# ETK-DEMO register map
Vendor: Embedded Toolkit (synthetic demo); File version: 1.0
Embedded Toolkit 演示芯片（合成数据，非真实芯片）
CPU: CM4 r0p1, little endian
Registers are 32-bit, read-write, reset 0x0 unless marked. A register's access mark holds for its fields unless they carry their own. Offsets are from the block's base; lines under a group give offsets from that group; [hi:lo] are bit positions; {n}, {i} and the like mark numbered series; 'fields as' and 'values as' point back to an identical list; <NAME> marks a mode.

## Memory map
0x40010400 EXTI size 0x400 — 外部中断（演示：4 条线）
0x40012C00 TIM1 size 0x400 — 高级定时器（演示）
0x40013800 USART1 size 0x400 — 通用同步/异步收发器（演示）
0x40020000 DMA1 size 0x400 — 直接内存访问控制器（演示：2 个通道，簇结构）
0x40021000 RCC size 0x400 — 复位与时钟控制（演示）
0x48000000 GPIOA size 0x400 — 通用 GPIO（演示：4 个引脚）
0x48000400 GPIOB size 0x400

## Interrupts
6 EXTI0 (EXTI) — EXTI 线 0 中断
11 DMA1_Channel1 (DMA1) — DMA1 通道 1 中断
12 DMA1_Channel2 (DMA1) — DMA1 通道 2 中断
25 TIM1 — TIM1 全局中断
37 USART1 — USART1 全局中断

## GPIOA — 通用 GPIO（演示：4 个引脚）
Base 0x48000000
Same registers: GPIOB 0x48000400
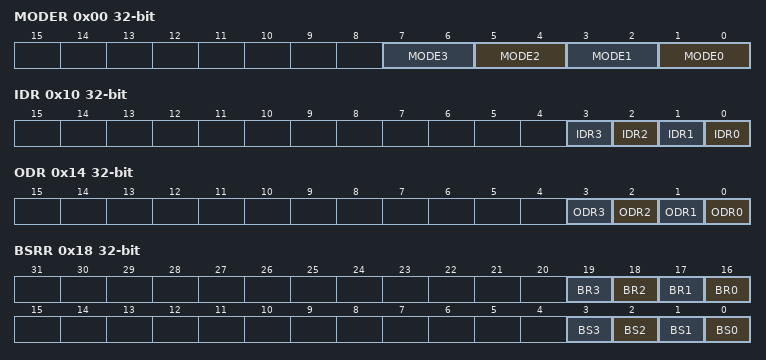
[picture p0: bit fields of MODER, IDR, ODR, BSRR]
0x00 MODER — 模式寄存器（每引脚 2 位）
  [all] fields
    0=INPUT (输入); 1=OUTPUT (输出); 2=ALTERNATE (复用功能); 3=ANALOG (模拟)
  [2n+1:2n] MODE{n} (n=0..3) — 引脚 {n} 模式
0x10 IDR ro — 输入数据寄存器（只读）
  [n] IDR{n} (n=0..3) — 引脚 {n} 输入
0x14 ODR — 输出数据寄存器
  [n] ODR{n} (n=0..3) — 引脚 {n} 输出
0x18 BSRR wo — 位置位/复位寄存器（只写）
  [n+16] BR{n} (n=0..3) — 复位引脚 {n}
  [n] BS{n} (n=0..3) — 置位引脚 {n}

## USART1 — 通用同步/异步收发器（演示）
Base 0x40013800
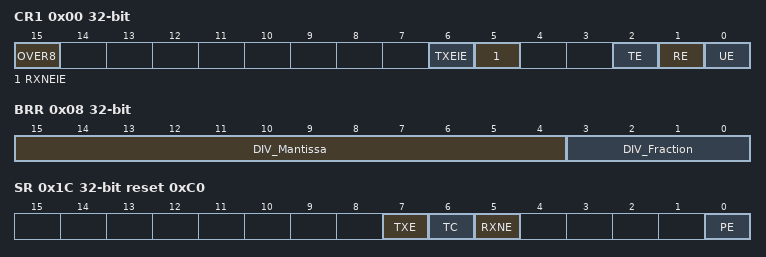
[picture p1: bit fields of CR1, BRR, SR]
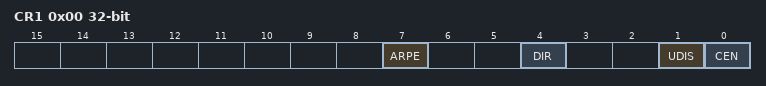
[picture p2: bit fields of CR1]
0x00 CR1 — 控制寄存器 1
  [15] OVER8 — 8 倍过采样
  [6] TXEIE — 发送空中断使能
  [5] RXNEIE — 接收完成中断使能
  [2] TE — 发送使能
  [1] RE — 接收使能
  [0] UE — USART 使能
0x04 DR — 数据寄存器
  [8:0] DR — 收发数据（低 9 位）
0x08 BRR — 波特率寄存器
  [15:4] DIV_Mantissa — 波特率分频整数部分
  [3:0] DIV_Fraction — 波特率分频小数部分
0x1C SR ro reset 0xC0 — 状态寄存器（只读）
  [7] TXE — 发送数据寄存器空
  [6] TC — 发送完成
  [5] RXNE — 接收数据非空
  [0] PE — 校验错误

## TIM1 — 高级定时器（演示）
Base 0x40012C00
0x00 CR1 — 控制寄存器 1
  [7] ARPE — 自动重载预装载使能
  [4] DIR — 计数方向
    0=UP (向上计数); 1=DOWN (向下计数)
  [1] UDIS — 更新事件禁止
  [0] CEN — 计数器使能
0x24 CNT ro — 计数器（只读）
  [15:0] CNT — 当前计数值
0x28 PSC — 预分频器
  [15:0] PSC — 预分频值
0x2C ARR — 自动重载寄存器
  [15:0] ARR — 自动重载值

## RCC — 复位与时钟控制（演示）
Base 0x40021000
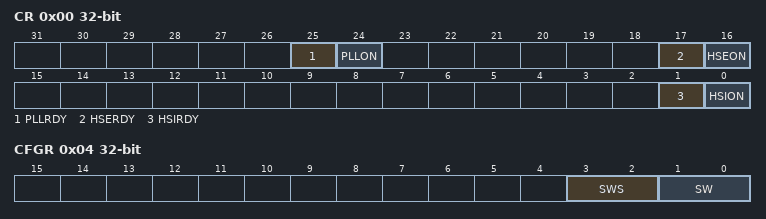
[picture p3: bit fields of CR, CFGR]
0x00 CR — 时钟控制寄存器
  [25] PLLRDY ro — PLL 就绪（只读）
  [24] PLLON — PLL 使能
  [17] HSERDY ro — 外部高速时钟就绪（只读）
  [16] HSEON — 外部高速时钟使能
  [1] HSIRDY ro — 内部高速时钟就绪（只读）
  [0] HSION — 内部高速时钟使能
0x04 CFGR — 时钟配置寄存器
  [3:2] SWS ro — 当前系统时钟源（只读）
  [1:0] SW — 系统时钟源选择
    0=HSI (内部高速时钟); 1=HSE (外部高速时钟); 2=PLL (PLL 输出)

## EXTI — 外部中断（演示：4 条线）
Base 0x40010400
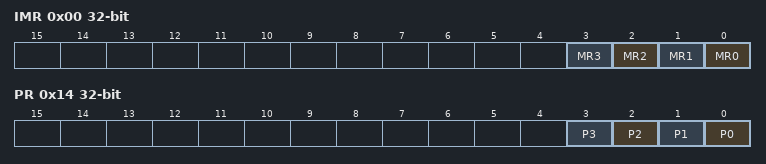
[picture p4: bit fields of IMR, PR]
0x00 IMR — 中断屏蔽寄存器
  [n] MR{n} (n=0..3) — 线 {n} 中断屏蔽
0x14 PR write-1-clears — 挂起寄存器（写 1 清零）
  [n] P{n} (n=0..3) — 线 {n} 挂起

## DMA1 — 直接内存访问控制器（演示：2 个通道，簇结构）
Base 0x40020000
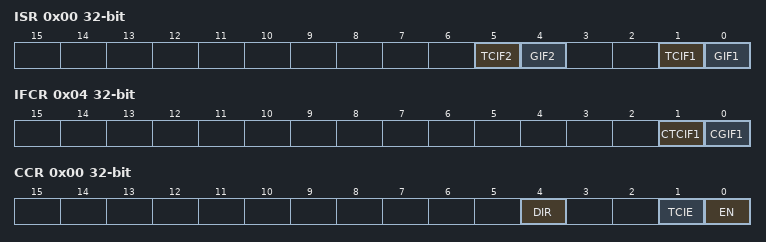
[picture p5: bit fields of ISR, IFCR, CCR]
0x00 ISR ro — 中断状态寄存器（只读）
  [5] TCIF2 — 通道 2 传输完成标志
  [4] GIF2 — 通道 2 全局中断标志
  [1] TCIF1 — 通道 1 传输完成标志
  [0] GIF1 — 通道 1 全局中断标志
0x04 IFCR write-1-clears — 中断标志清除寄存器（写 1 清零）
  [1] CTCIF1 — 清除通道 1 传输完成标志
  [0] CGIF1 — 清除通道 1 全局标志
0x08 CH1 group — 通道 1 寄存器组
  0x00 CCR — 通道配置寄存器
    [4] DIR — 数据方向
      0=P2M (外设到内存); 1=M2P (内存到外设)
    [1] TCIE — 传输完成中断使能
    [0] EN — 通道使能
  0x04 CNDTR — 传输数量寄存器
    [15:0] NDT — 待传输数量
  0x08 CPAR — 外设地址寄存器
    [31:0] PA — 外设地址
  0x0C CMAR — 内存地址寄存器
    [31:0] MA — 内存地址
0x1C CH2 group — 通道 2 寄存器组
  0x00 CCR — 通道配置寄存器
    fields as CH1.CCR
  0x04 CNDTR — 传输数量寄存器
    [15:0] NDT — 待传输数量
  0x08 CPAR — 外设地址寄存器
    [31:0] PA — 外设地址
  0x0C CMAR — 内存地址寄存器
    [31:0] MA — 内存地址
